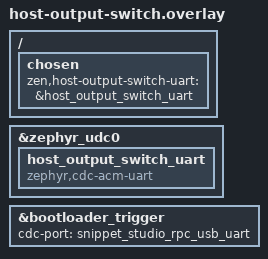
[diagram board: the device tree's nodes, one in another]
/*
 * A second CDC ACM port, used only by src/host_output_switch.c.
 * List this snippet after studio-rpc-usb-uart: the Studio port keeps the
 * first interface, and the bootloader trigger is pinned to it so the
 * 1200-baud reset keeps working on the port tools already use.
 */

/ {
    chosen {
        zen,host-output-switch-uart = &host_output_switch_uart;
    };
};

&zephyr_udc0 {
    host_output_switch_uart: host_output_switch_uart {
        compatible = "zephyr,cdc-acm-uart";
    };
};

&bootloader_trigger {
    cdc-port = <&snippet_studio_rpc_usb_uart>;
};
